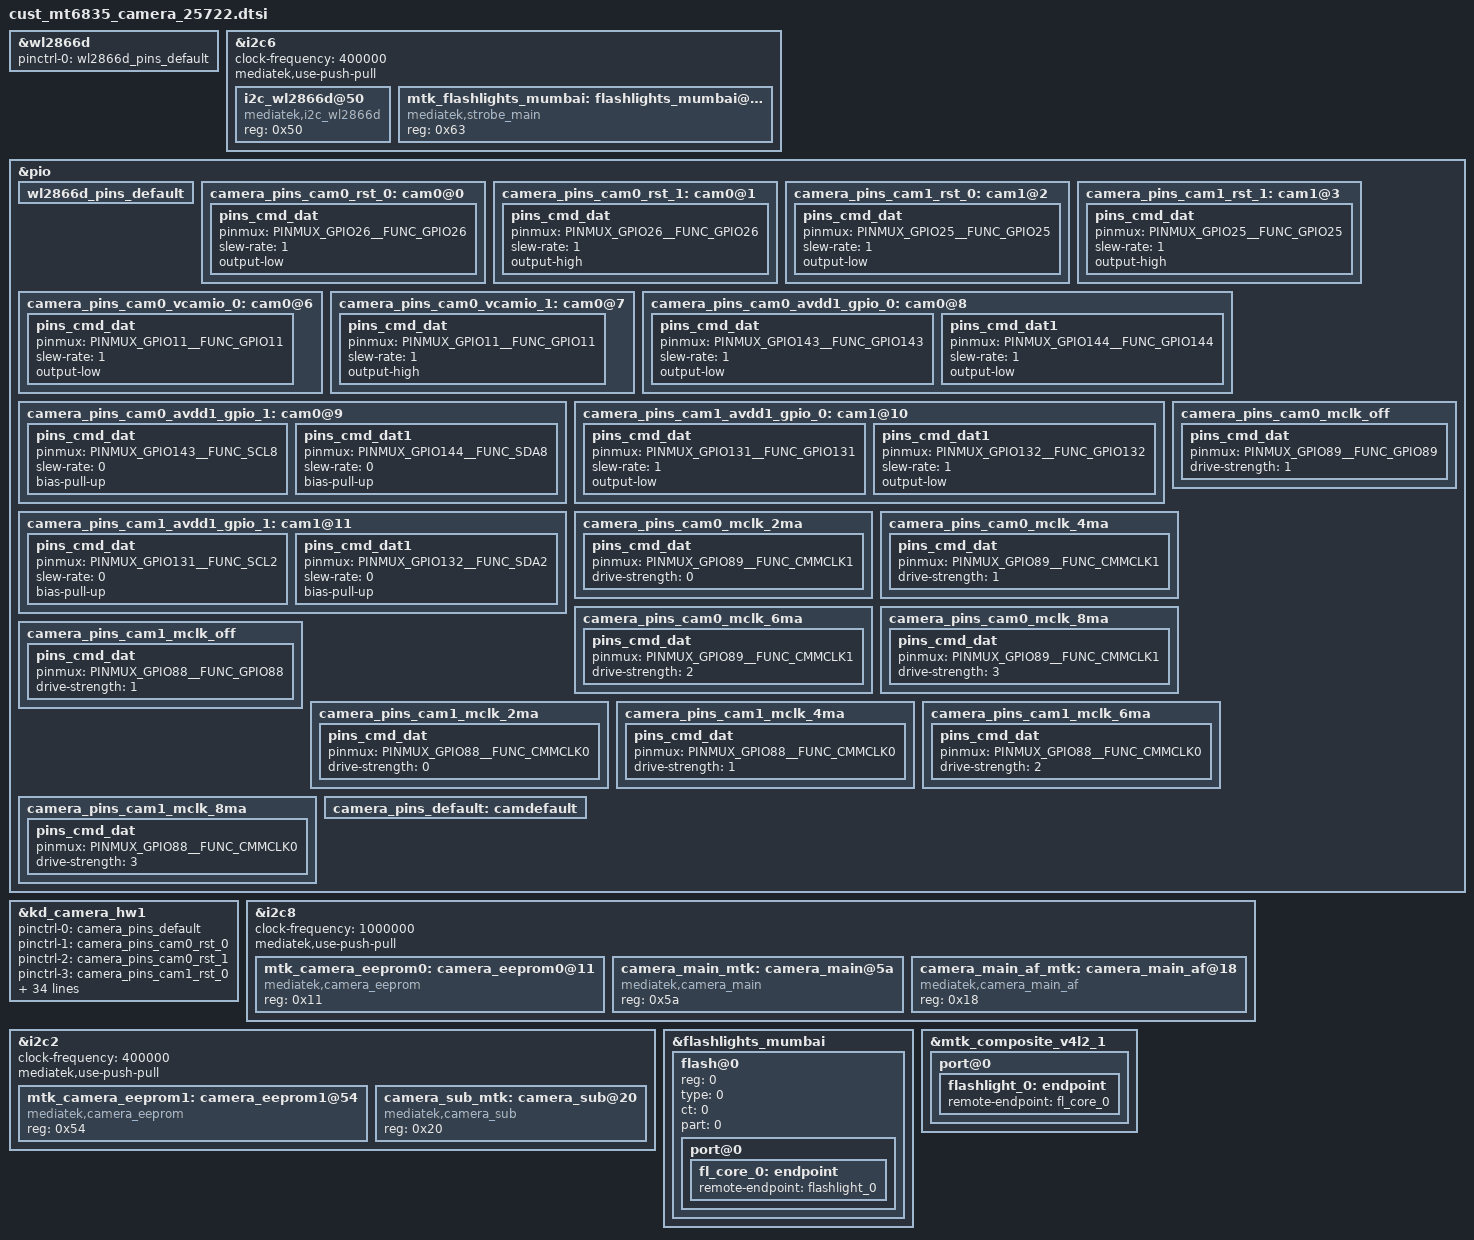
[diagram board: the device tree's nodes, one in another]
// SPDX-License-Identifier: GPL-2.0
/* Copyright (c) 2020 MediaTek Inc. */
/* CAMERA GPIO standardization */

&wl2866d {
		pinctrl-names = "default";
		pinctrl-0 = <&wl2866d_pins_default>;
		status = "okay";
};

&i2c6 {
	status = "okay";
	clock-frequency = <400000>;
	mediatek,use-push-pull;
	#address-cells = <1>;
	#size-cells = <0>;
	i2c_wl2866d@50{
		compatible = "mediatek,i2c_wl2866d";
		reg = <0x50>;
		status = "okay";
	};
};
/*wl2866d pinctrl*/
&pio {
	wl2866d_pins_default: wl2866d_pins_default {
	};
};

/*camera power pinctrl*/
&pio {
	camera_pins_cam0_rst_0: cam0@0 {
		pins_cmd_dat {
			pinmux = <PINMUX_GPIO26__FUNC_GPIO26>;
			slew-rate = <1>;
			output-low;
		};
	};
	camera_pins_cam0_rst_1: cam0@1 {
		pins_cmd_dat {
			pinmux = <PINMUX_GPIO26__FUNC_GPIO26>;
			slew-rate = <1>;
			output-high;
		};
	};
	camera_pins_cam1_rst_0: cam1@2 {
		pins_cmd_dat {
			pinmux = <PINMUX_GPIO25__FUNC_GPIO25>;
			slew-rate = <1>;
			output-low;
		};
	};
	camera_pins_cam1_rst_1: cam1@3 {
		pins_cmd_dat {
			pinmux = <PINMUX_GPIO25__FUNC_GPIO25>;
			slew-rate = <1>;
			output-high;
		};
	};
	camera_pins_cam0_vcamio_0: cam0@6 {
		pins_cmd_dat {
			pinmux = <PINMUX_GPIO11__FUNC_GPIO11>;
			slew-rate = <1>;
			output-low;
		};
	};
	camera_pins_cam0_vcamio_1: cam0@7 {
		pins_cmd_dat {
			pinmux = <PINMUX_GPIO11__FUNC_GPIO11>;
			slew-rate = <1>;
			output-high;
		};
	};
	camera_pins_cam0_avdd1_gpio_0: cam0@8 {
		pins_cmd_dat {
			pinmux = <PINMUX_GPIO143__FUNC_GPIO143>;
			slew-rate = <1>;
			output-low;
		};
		pins_cmd_dat1 {
			pinmux = <PINMUX_GPIO144__FUNC_GPIO144>;
			slew-rate = <1>;
			output-low;
		};
	};
	camera_pins_cam0_avdd1_gpio_1: cam0@9 {
		pins_cmd_dat {
			pinmux = <PINMUX_GPIO143__FUNC_SCL8>;
			slew-rate = <0>;
			bias-pull-up;
		};
		pins_cmd_dat1 {
			pinmux = <PINMUX_GPIO144__FUNC_SDA8>;
			slew-rate = <0>;
			bias-pull-up;
		};
	};
	camera_pins_cam1_avdd1_gpio_0: cam1@10 {
		pins_cmd_dat {
			pinmux = <PINMUX_GPIO131__FUNC_GPIO131>;
			slew-rate = <1>;
			output-low;
		};
		pins_cmd_dat1 {
			pinmux = <PINMUX_GPIO132__FUNC_GPIO132>;
			slew-rate = <1>;
			output-low;
		};
	};
	camera_pins_cam1_avdd1_gpio_1: cam1@11 {
		pins_cmd_dat {
			pinmux = <PINMUX_GPIO131__FUNC_SCL2>;
			slew-rate = <0>;
			bias-pull-up;
		};
		pins_cmd_dat1 {
			pinmux = <PINMUX_GPIO132__FUNC_SDA2>;
			slew-rate = <0>;
			bias-pull-up;
		};
	};
	camera_pins_cam0_mclk_off: camera_pins_cam0_mclk_off {
		pins_cmd_dat {
			pinmux = <PINMUX_GPIO89__FUNC_GPIO89>;
			drive-strength = <1>;
		};
	};
	camera_pins_cam0_mclk_2ma: camera_pins_cam0_mclk_2ma {
		pins_cmd_dat {
			pinmux = <PINMUX_GPIO89__FUNC_CMMCLK1>;
			drive-strength = <0>;
		};
	};
	camera_pins_cam0_mclk_4ma: camera_pins_cam0_mclk_4ma {
		pins_cmd_dat {
			pinmux = <PINMUX_GPIO89__FUNC_CMMCLK1>;
			drive-strength = <1>;
		};
	};
	camera_pins_cam0_mclk_6ma: camera_pins_cam0_mclk_6ma {
		pins_cmd_dat {
			pinmux = <PINMUX_GPIO89__FUNC_CMMCLK1>;
			drive-strength = <2>;
		};
	};
	camera_pins_cam0_mclk_8ma: camera_pins_cam0_mclk_8ma {
		pins_cmd_dat {
			pinmux = <PINMUX_GPIO89__FUNC_CMMCLK1>;
			drive-strength = <3>;
		};
	};
	camera_pins_cam1_mclk_off: camera_pins_cam1_mclk_off {
		pins_cmd_dat {
			pinmux = <PINMUX_GPIO88__FUNC_GPIO88>;
			drive-strength = <1>;
		};
	};
	camera_pins_cam1_mclk_2ma: camera_pins_cam1_mclk_2ma {
		pins_cmd_dat {
			pinmux = <PINMUX_GPIO88__FUNC_CMMCLK0>;
			drive-strength = <0>;
		};
	};
	camera_pins_cam1_mclk_4ma: camera_pins_cam1_mclk_4ma {
		pins_cmd_dat {
			pinmux = <PINMUX_GPIO88__FUNC_CMMCLK0>;
			drive-strength = <1>;
		};
	};
	camera_pins_cam1_mclk_6ma: camera_pins_cam1_mclk_6ma {
		pins_cmd_dat {
			pinmux = <PINMUX_GPIO88__FUNC_CMMCLK0>;
			drive-strength = <2>;
		};
	};
	camera_pins_cam1_mclk_8ma: camera_pins_cam1_mclk_8ma {
		pins_cmd_dat {
			pinmux = <PINMUX_GPIO88__FUNC_CMMCLK0>;
			drive-strength = <3>;
		};
	};
	camera_pins_default: camdefault {
	};
};
&kd_camera_hw1 {
	pinctrl-names = "default",
			"cam0_rst0", "cam0_rst1",
			"cam1_rst0", "cam1_rst1",
			"cam0_ldo_vcamio_0","cam0_ldo_vcamio_1",
			"cam0_mclk_off",
			"cam0_mclk_2mA", "cam0_mclk_4mA",
			"cam0_mclk_6mA", "cam0_mclk_8mA",
			"cam1_mclk_off",
			"cam1_mclk_2mA", "cam1_mclk_4mA",
			"cam1_mclk_6mA", "cam1_mclk_8mA",
			"cam0_avdd1_gpio_0", "cam0_avdd1_gpio_1",
			"cam1_avdd1_gpio_0", "cam1_avdd1_gpio_1";

	pinctrl-0 = <&camera_pins_default>;
	pinctrl-1 = <&camera_pins_cam0_rst_0>;
	pinctrl-2 = <&camera_pins_cam0_rst_1>;
	pinctrl-3 = <&camera_pins_cam1_rst_0>;
	pinctrl-4 = <&camera_pins_cam1_rst_1>;
	pinctrl-5 = <&camera_pins_cam0_vcamio_0>;
	pinctrl-6 = <&camera_pins_cam0_vcamio_1>;
	pinctrl-7 = <&camera_pins_cam0_mclk_off>;
	pinctrl-8 = <&camera_pins_cam0_mclk_2ma>;
	pinctrl-9 = <&camera_pins_cam0_mclk_4ma>;
	pinctrl-10 = <&camera_pins_cam0_mclk_6ma>;
	pinctrl-11 = <&camera_pins_cam0_mclk_8ma>;
	pinctrl-12 = <&camera_pins_cam1_mclk_off>;
	pinctrl-13 = <&camera_pins_cam1_mclk_2ma>;
	pinctrl-14 = <&camera_pins_cam1_mclk_4ma>;
	pinctrl-15 = <&camera_pins_cam1_mclk_6ma>;
	pinctrl-16 = <&camera_pins_cam1_mclk_8ma>;
	pinctrl-17 = <&camera_pins_cam0_avdd1_gpio_0>;
	pinctrl-18 = <&camera_pins_cam0_avdd1_gpio_1>;
	pinctrl-19 = <&camera_pins_cam1_avdd1_gpio_0>;
	pinctrl-20 = <&camera_pins_cam1_avdd1_gpio_1>;


	cam0_vcamio-supply = <&mt6377_vaud18>;
	cam1_vcamio-supply = <&mt6377_vaud18>;

	cam0_pin_mclk = "mclk";
	cam0_pin_rst = "gpio";
	cam0_pin_vcama = "wl2866d";
	cam0_pin_vcamio = "regulator";
	cam0_pin_vcamd = "wl2866d";
	cam0_pin_vcamaf = "wl2866d";
	cam0_pin_vcama1_gpio = "gpio";
	cam1_pin_mclk = "mclk";
	cam1_pin_rst = "gpio";
	cam1_pin_vcama = "wl2866d";
	cam1_pin_vcamio = "regulator";
	cam1_pin_vcamd = "wl2866d";
	cam1_pin_vcama1_gpio = "gpio";

	cam0_enable_sensor = "ov13b10_mipi_raw_mumbai";
	cam1_enable_sensor = "mt510_mipi_raw_mumbai";
	status = "okay";
};
/* CAMERA GPIO end */

/* CAMERA EEPROM */
&i2c8 {
	status = "okay";
	clock-frequency = <1000000>;
	mediatek,use-push-pull;
	#address-cells = <1>;
	#size-cells = <0>;

	mtk_camera_eeprom0:camera_eeprom0@11 {
		compatible = "mediatek,camera_eeprom";
		reg = <0x11>;
		status = "okay";
	};
	camera_main_mtk:camera_main@5a {
		compatible = "mediatek,camera_main";
		#thermal-sensor-cells = <0>;
		reg = <0x5a>;
		status = "okay";
	};
	camera_main_af_mtk:camera_main_af@18 {
		compatible = "mediatek,camera_main_af";
		reg = <0x18>;
		status = "okay";
	};
};

&i2c2 {
	status = "okay";
	clock-frequency = <400000>;
	mediatek,use-push-pull;
	#address-cells = <1>;
	#size-cells = <0>;

	mtk_camera_eeprom1:camera_eeprom1@54 {
		compatible = "mediatek,camera_eeprom";
		reg = <0x54>;
		status = "okay";
	};
	camera_sub_mtk:camera_sub@20 {
		compatible = "mediatek,camera_sub";
		#thermal-sensor-cells = <0>;
		reg = <0x20>;
		status = "okay";
	};
};


&i2c6 {
	status = "okay";
	clock-frequency = <400000>;
	mediatek,use-push-pull;
        #address-cells = <1>;
        #size-cells = <0>;

	mtk_flashlights_mumbai:flashlights_mumbai@63 {
		compatible = "mediatek,strobe_main";
		reg = <0x63>;
		status = "okay";
	};
};

&flashlights_mumbai {
	status = "okay";
	flash@0{
		reg = <0>;
		type = <0>;
		ct = <0>;
		part = <0>;
		port@0 {
			fl_core_0: endpoint {
				remote-endpoint = <&flashlight_0>;
			};
		};
	};
};


&mtk_composite_v4l2_1 {
	port@0 {
		flashlight_0: endpoint {
			remote-endpoint = <&fl_core_0>;
		};
	};
};


/* CAMERA EEPROM end */

